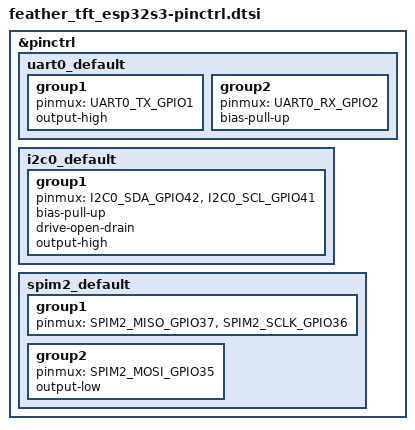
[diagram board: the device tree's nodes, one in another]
/*
 * Copyright (c) 2022 Espressif Systems (Shanghai) Co., Ltd.
 *
 * SPDX-License-Identifier: Apache-2.0
 *
 * Derived from zephyr/boards/espressif/esp32s3_devkitm
 * Modifications by Sam Blenny to work with Feather TFT ESP32-S3
 * For SPI config docs, see:
 *    https://docs.zephyrproject.org/latest/build/dts/api/bindings/spi/espressif%2Cesp32-spi.html
 * For a list of ESP32-S3 pinctrl selectors, see:
 *   https://github.com/zephyrproject-rtos/zephyr/blob/main/include/zephyr/dt-bindings/pinctrl/esp32s3-pinctrl.h
 */

#include <zephyr/dt-bindings/pinctrl/esp-pinctrl-common.h>
#include <dt-bindings/pinctrl/esp32s3-pinctrl.h>
#include <zephyr/dt-bindings/pinctrl/esp32s3-gpio-sigmap.h>

&pinctrl {
	/* Feather header UART pins: RX: GPIO2, TX: GPIO1 */
	uart0_default: uart0_default {
		group1 {
			pinmux = <UART0_TX_GPIO1>;
			output-high;
		};
		group2 {
			pinmux = <UART0_RX_GPIO2>;
			bias-pull-up;
		};
	};

	/* Feather header / STEMMA QT I2C pins: SDA: GPIO42, SCL: GPIO41 */
	i2c0_default: i2c0_default {
		group1 {
			pinmux = <I2C0_SDA_GPIO42>,
				 <I2C0_SCL_GPIO41>;
			bias-pull-up;
			drive-open-drain;
			output-high;
		};
	};

	/* Feather header SPI pins: SCK: GPIO36, MO: GPIO35, MI: GPIO37 */
	/* group1: MISO, SCK, [optional CS]; group2: MOSI */
	spim2_default: spim2_default {
		group1 {
			pinmux =
				<SPIM2_MISO_GPIO37>,  /* Feather MISO */
				<SPIM2_SCLK_GPIO36>;  /* Feather SCK / TFT SCK */
		};
		group2 {
			pinmux = <SPIM2_MOSI_GPIO35>;  /* Feather MOSI / TFT MOSI */
			output-low;
		};
	};

};
